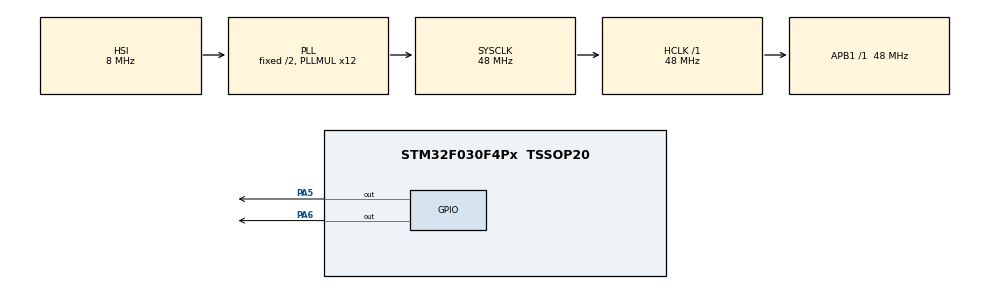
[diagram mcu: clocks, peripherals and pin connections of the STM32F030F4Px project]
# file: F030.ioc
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Mcu.Family=STM32F0
Mcu.Name=STM32F030F4Px
Mcu.Package=TSSOP20
PA13.Mode=Serial-WireDebug
PA13.Signal=SYS_SWDIO
PA14.Mode=Serial-WireDebug
PA14.Signal=SYS_SWCLK
PA5.Signal=GPIO_Output
PA6.Signal=GPIO_Output
ProjectManager.TargetToolchain=SW4STM32
RCC.AHBFreq_Value=48000000
RCC.APB1Freq_Value=48000000
RCC.APB1TimFreq_Value=48000000
RCC.HCLKFreq_Value=48000000
RCC.PLLMUL=RCC_PLL_MUL12
RCC.SYSCLKFreq_VALUE=48000000
RCC.SYSCLKSource=RCC_SYSCLKSOURCE_PLLCLK
board=F030

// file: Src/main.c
/**
  ******************************************************************************
  * File Name          : main.c
  * Description        : Main program body
  ******************************************************************************
  *
  * COPYRIGHT(c) 2016 STMicroelectronics
  *
  * Redistribution and use in source and binary forms, with or without modification,
  * are permitted provided that the following conditions are met:
  *   1. Redistributions of source code must retain the above copyright notice,
  *      this list of conditions and the following disclaimer.
  *   2. Redistributions in binary form must reproduce the above copyright notice,
  *      this list of conditions and the following disclaimer in the documentation
  *      and/or other materials provided with the distribution.
  *   3. Neither the name of STMicroelectronics nor the names of its contributors
  *      may be used to endorse or promote products derived from this software
  *      without specific prior written permission.
  *
  * THIS SOFTWARE IS PROVIDED BY THE COPYRIGHT HOLDERS AND CONTRIBUTORS "AS IS"
  * AND ANY EXPRESS OR IMPLIED WARRANTIES, INCLUDING, BUT NOT LIMITED TO, THE
  * IMPLIED WARRANTIES OF MERCHANTABILITY AND FITNESS FOR A PARTICULAR PURPOSE ARE
  * DISCLAIMED. IN NO EVENT SHALL THE COPYRIGHT HOLDER OR CONTRIBUTORS BE LIABLE
  * FOR ANY DIRECT, INDIRECT, INCIDENTAL, SPECIAL, EXEMPLARY, OR CONSEQUENTIAL
  * DAMAGES (INCLUDING, BUT NOT LIMITED TO, PROCUREMENT OF SUBSTITUTE GOODS OR
  * SERVICES; LOSS OF USE, DATA, OR PROFITS; OR BUSINESS INTERRUPTION) HOWEVER
  * CAUSED AND ON ANY THEORY OF LIABILITY, WHETHER IN CONTRACT, STRICT LIABILITY,
  * OR TORT (INCLUDING NEGLIGENCE OR OTHERWISE) ARISING IN ANY WAY OUT OF THE USE
  * OF THIS SOFTWARE, EVEN IF ADVISED OF THE POSSIBILITY OF SUCH DAMAGE.
  *
  ******************************************************************************
  */
#include "stm32f0xx_hal.h"

/* USER CODE BEGIN PV */
/* Private variables ---------------------------------------------------------*/

/* USER CODE END PV */

void SystemClock_Config(void);
static void MX_GPIO_Init(void);

/* USER CODE BEGIN PFP */
/* Private function prototypes -----------------------------------------------*/

/* USER CODE END PFP */

int main(void)
{

  /* MCU Configuration----------------------------------------------------------*/

  /* Reset of all peripherals, Initializes the Flash interface and the Systick. */
  HAL_Init();

  /* Configure the system clock */
  SystemClock_Config();

  /* Initialize all configured peripherals */
  MX_GPIO_Init();

  /* Infinite loop */
  /* USER CODE BEGIN WHILE */
  HAL_GPIO_WritePin(GPIOA, GPIO_PIN_5, GPIO_PIN_SET);
  HAL_GPIO_WritePin(GPIOA, GPIO_PIN_6, GPIO_PIN_RESET);
  //HAL_Delay(1);
  HAL_GPIO_TogglePin(GPIOA, GPIO_PIN_5);
  //HAL_Delay(1);
  HAL_GPIO_TogglePin(GPIOA, GPIO_PIN_5);
  while (1)
  {
	  //HAL_Delay(100);
	  HAL_GPIO_TogglePin(GPIOA, GPIO_PIN_5);
  /* USER CODE END WHILE */

  }

}

/** System Clock Configuration
*/
void SystemClock_Config(void)
{

  RCC_OscInitTypeDef RCC_OscInitStruct;
  RCC_ClkInitTypeDef RCC_ClkInitStruct;

  RCC_OscInitStruct.OscillatorType = RCC_OSCILLATORTYPE_HSI;
  RCC_OscInitStruct.HSIState = RCC_HSI_ON;
  RCC_OscInitStruct.HSICalibrationValue = 16;
  RCC_OscInitStruct.PLL.PLLState = RCC_PLL_ON;
  RCC_OscInitStruct.PLL.PLLSource = RCC_PLLSOURCE_HSI;
  RCC_OscInitStruct.PLL.PLLMUL = RCC_PLL_MUL12;
  RCC_OscInitStruct.PLL.PREDIV = RCC_PREDIV_DIV1;
  HAL_RCC_OscConfig(&RCC_OscInitStruct);

  RCC_ClkInitStruct.ClockType = RCC_CLOCKTYPE_SYSCLK;
  RCC_ClkInitStruct.SYSCLKSource = RCC_SYSCLKSOURCE_PLLCLK;
  RCC_ClkInitStruct.AHBCLKDivider = RCC_SYSCLK_DIV1;
  RCC_ClkInitStruct.APB1CLKDivider = RCC_HCLK_DIV1;
  HAL_RCC_ClockConfig(&RCC_ClkInitStruct, FLASH_LATENCY_1);

  HAL_SYSTICK_Config(HAL_RCC_GetHCLKFreq()/1000);

  HAL_SYSTICK_CLKSourceConfig(SYSTICK_CLKSOURCE_HCLK);

  /* SysTick_IRQn interrupt configuration */
  HAL_NVIC_SetPriority(SysTick_IRQn, 0, 0);
}

/** Configure pins as
        * Analog
        * Input
        * Output
        * EVENT_OUT
        * EXTI
*/
void MX_GPIO_Init(void)
{

  GPIO_InitTypeDef GPIO_InitStruct;

  /* GPIO Ports Clock Enable */
  __GPIOA_CLK_ENABLE();

  /*Configure GPIO pins : PA5 PA6 */
  GPIO_InitStruct.Pin = GPIO_PIN_5|GPIO_PIN_6;
  GPIO_InitStruct.Mode = GPIO_MODE_OUTPUT_PP;
  GPIO_InitStruct.Pull = GPIO_NOPULL;
  GPIO_InitStruct.Speed = GPIO_SPEED_LOW;
  HAL_GPIO_Init(GPIOA, &GPIO_InitStruct);

}

/************************ (C) COPYRIGHT STMicroelectronics *****END OF FILE****/
